# GD32E511_512 register map
File version: 1.0
CPU: CM33 r0p4, little endian, MPU, FPU, 4 interrupt priority bits
Registers are 32-bit, read-write, reset 0x0 unless marked. A register's access mark holds for its fields unless they carry their own. Offsets are from the block's base; [hi:lo] are bit positions; {n}, {i} and the like mark numbered series.

## DBGMCU — Debug support
Base 0xE0044000
0x00 ID ro — MCU Device ID Code Register
  [31:0] ID_CODE — DBG ID code register
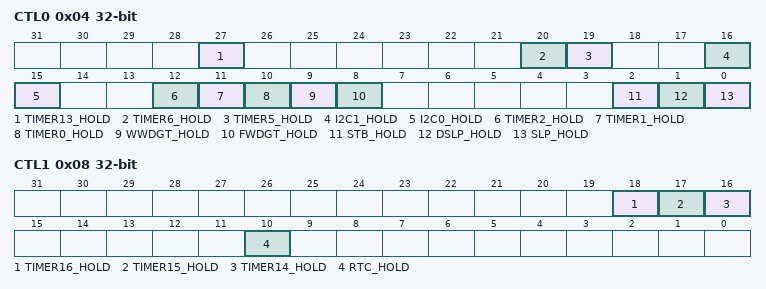
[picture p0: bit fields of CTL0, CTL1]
0x04 CTL0 — Debug Control Register 0
  [27] TIMER13_HOLD — Timer 13 hold bit
  [20] TIMER6_HOLD — Timer 6 hold bit
  [19] TIMER5_HOLD — Timer 5 hold bit
  [16] I2C1_HOLD — I2C1 hold bit
  [15] I2C0_HOLD — I2C0 hold bit
  [12] TIMER2_HOLD — Timer 2 hold bit
  [11] TIMER1_HOLD — Timer 1 hold bit
  [10] TIMER0_HOLD — Timer 0 hold bit
  [9] WWDGT_HOLD — WWDGT hold bit
  [8] FWDGT_HOLD — FWDGT hold bit
  [2] STB_HOLD — Standby mode hold Mode
  [1] DSLP_HOLD — DEEPSLEEP mode hold Mode
  [0] SLP_HOLD — Sleep mode hold register
0x08 CTL1 — Debug Control Register 1
  [18] TIMER16_HOLD — Timer 16 hold bit
  [17] TIMER15_HOLD — Timer 15 hold bit
  [16] TIMER14_HOLD — Timer 14 hold bit
  [10] RTC_HOLD — RTC hold bit

## DMA — DMA controller
Base 0x40020000
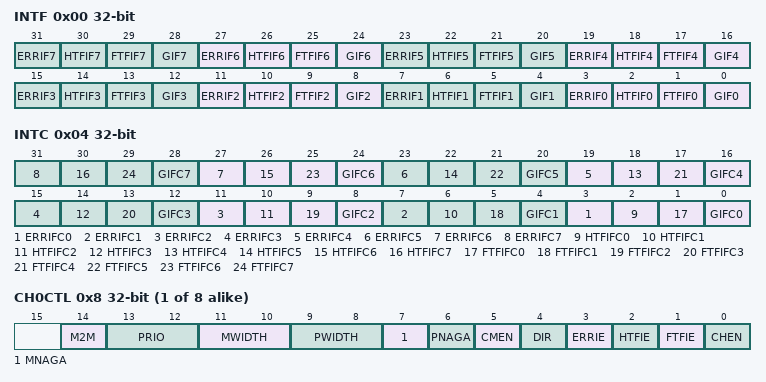
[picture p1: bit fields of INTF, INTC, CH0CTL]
0x00 INTF ro — Interrupt flag register
  [4n+3] ERRIF{n} (n=0..7) — Error flag of channel {n}
  [4n+2] HTFIF{n} (n=0..7) — Half transfer finish flag of channel {n}
  [4n+1] FTFIF{n} (n=0..7) — Full Transfer finish flag of channel {n}
  [4n] GIF{n} (n=0..7) — Global interrupt flag of channel {n}
0x04 INTC wo — Interrupt flag clear register
  [4n+3] ERRIFC{n} (n=0..7) — Clear bit for error flag of channel {n}
  [4n+2] HTFIFC{n} (n=0..7) — Clear bit for half transfer finish flag of channel {n}
  [4n+1] FTFIFC{n} (n=0..7) — Clear bit for full transfer finish flag of channel {n}
  [4n] GIFC{n} (n=0..7) — Clear global interrupt flag of channel {n}
{0x8+0x14*i} CH{i}CTL (i=0..7) — Channel {i} control regist
  [14] M2M — Memory to Memory mode
  [13:12] PRIO — Priority level
  [11:10] MWIDTH — Transfer data size of memory
  [9:8] PWIDTH — Transfer data size of peripheral
  [7] MNAGA — Next address generation algorithm of memory
  [6] PNAGA — Next address generation algorithm of peripheral
  [5] CMEN — Circular mode enable
  [4] DIR — Transfer direction
  [3] ERRIE — Enable bit for channel error interrupt
  [2] HTFIE — Enable bit for channel half transfer finish interrupt
  [1] FTFIE — Enable bit for channel full transfer finish interrupt
  [0] CHEN — Channel enable
{0xC+0x14*i} CH{i}CNT (i=0..7) — Channel {i} counter regist
  [15:0] CNT — Transfer counter
{0x10+0x14*i} CH{i}PADDR (i=0..7) — Channel {i} peripheral base address regist
  [31:0] PADDR — Peripheral base address
{0x14+0x14*i} CH{i}MADDR (i=0..7) — Channel {i} memory base address regist
  [31:0] MADDR — Memory base address

## EXTI — External interrupt/event controller
Base 0x40010400
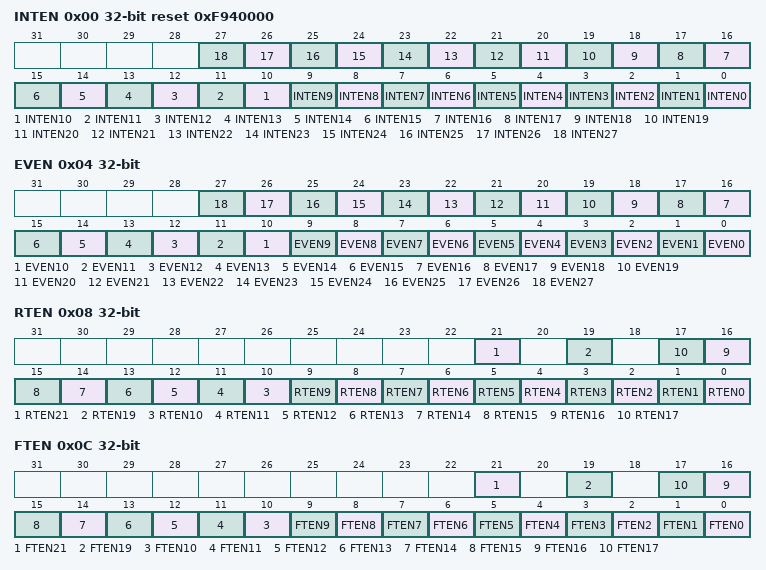
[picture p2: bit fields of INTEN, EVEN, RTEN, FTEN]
0x00 INTEN reset 0xF940000 — Interrupt enable register (EXTI_INTEN)
  [n] INTEN{n} (n=0..27) — Enable Interrupt on line {n}
0x04 EVEN — Event enable register (EXTI_EVEN)
  [n] EVEN{n} (n=0..27) — Enable Event on line {n}
0x08 RTEN — Rising edge trigger enable register (EXTI_RTEN)
  [21] RTEN21 — Rising trigger event configuration of line 21
  [19] RTEN19 — Rising trigger event configuration of line 19
  [n] RTEN{n} (n=0..17) — Rising trigger event configuration of line {n}
0x0C FTEN — Falling egde trigger enable register (EXTI_FTEN)
  [21] FTEN21 — Falling trigger event configuration of line 21
  [19] FTEN19 — Falling trigger event configuration of line 19
  [n] FTEN{n} (n=0..17) — Falling trigger event configuration of line {n}
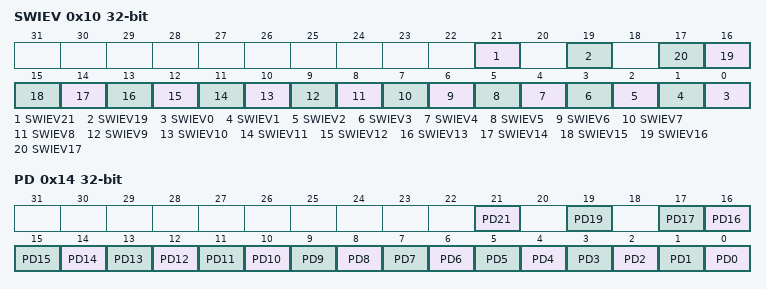
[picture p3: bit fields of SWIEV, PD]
0x10 SWIEV — Software interrupt event register (EXTI_SWIEV)
  [21] SWIEV21 — Software Interrupt on line 21
  [19] SWIEV19 — Software Interrupt on line 19
  [n] SWIEV{n} (n=0..17) — Software Interrupt on line {n}
0x14 PD — Pending register (EXTI_PD)
  [21] PD21 — Pending bit 21
  [19] PD19 — Pending bit 19
  [n] PD{n} (n=0..17) — Pending bit {n}
